# ATmega324PA register map
Vendor: Atmel; File version: 1.0
CPU: other r0p0, little endian, no MPU, no FPU, 4 interrupt priority bits
Registers are 8-bit, read-write, reset 0x0 unless marked. A register's access mark holds for its fields unless they carry their own. Offsets are from the block's base; [hi:lo] are bit positions.

## TC2 — Timer/Counter, 8-bit Async
Base 0x00000037
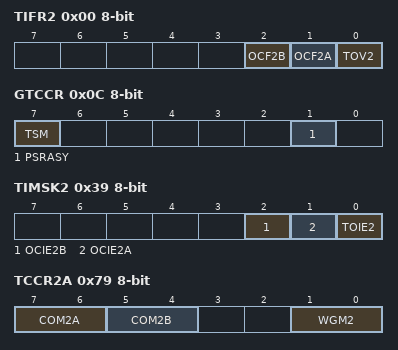
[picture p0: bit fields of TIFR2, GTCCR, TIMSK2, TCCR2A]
0x00 TIFR2 — Timer/Counter Interrupt Flag Register
  [2] OCF2B — Output Compare Flag 2B
  [1] OCF2A — Output Compare Flag 2A
  [0] TOV2 — Timer/Counter2 Overflow Flag
0x0C GTCCR — General Timer Counter Control register
  [7] TSM — Timer/Counter Synchronization Mode
  [1] PSRASY — Prescaler Reset Timer/Counter2
0x39 TIMSK2 — Timer/Counter Interrupt Mask register
  [2] OCIE2B — Timer/Counter2 Output Compare Match B Interrupt Enable
  [1] OCIE2A — Timer/Counter2 Output Compare Match A Interrupt Enable
  [0] TOIE2 — Timer/Counter2 Overflow Interrupt Enable
0x79 TCCR2A — Timer/Counter2 Control Register A
  [7:6] COM2A — Compare Output Mode bits
  [5:4] COM2B — Compare Output Mode bits
  [1:0] WGM2 — Waveform Genration Mode
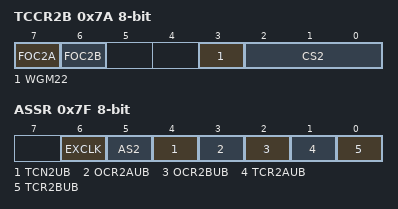
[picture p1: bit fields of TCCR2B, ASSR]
0x7A TCCR2B — Timer/Counter2 Control Register B
  [7] FOC2A — Force Output Compare A
  [6] FOC2B — Force Output Compare B
  [3] WGM22 — Waveform Generation Mode
  [2:0] CS2 — Clock Select bits
    0=No Clock Source (Stopped); 1=Running, No Prescaling; 2=Running, CLK/8; 3=Running, CLK/32; 4=Running, CLK/64; 5=Running, CLK/128; 6=Running, CLK/256; 7=Running, CLK/1024
0x7B TCNT2 — Timer/Counter2
  [7:0] TCNT2 — Timer/Counter2 bits
0x7C OCR2A — Timer/Counter2 Output Compare Register A
  [7:0] OCR2A — Timer/Counter0 Output Compare A bits
0x7D OCR2B — Timer/Counter2 Output Compare Register B
  [7:0] OCR2B — Timer/Counter2 Output Compare B bits
0x7F ASSR — Asynchronous Status Register
  [6] EXCLK — Enable External Clock Input
  [5] AS2 — Asynchronous Timer/Counter2
  [4] TCN2UB — Timer/Counter2 Update Busy
  [3] OCR2AUB — Output Compare Register2 Update Busy
  [2] OCR2BUB — Output Compare Register 2 Update Busy
  [1] TCR2AUB — Timer/Counter Control Register2 Update Busy
  [0] TCR2BUB — Timer/Counter Control Register2 Update Busy

## TWI — Two Wire Serial Interface
Base 0x000000B8
0x00 TWBR — TWI Bit Rate register
  [7:0] TWBR — TWI bit rate bits
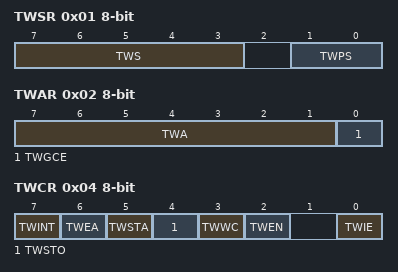
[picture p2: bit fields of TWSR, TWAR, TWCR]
0x01 TWSR — TWI Status Register
  [7:3] TWS — TWI Status
  [1:0] TWPS — TWI Prescaler
    0=1; 1=4; 2=16; 3=64
0x02 TWAR — TWI (Slave) Address register
  [7:1] TWA — TWI (Slave) Address register Bits
  [0] TWGCE — TWI General Call Recognition Enable Bit
0x03 TWDR — TWI Data register
  [7:0] TWD — TWI data bits
0x04 TWCR — TWI Control Register
  [7] TWINT — TWI Interrupt Flag
  [6] TWEA — TWI Enable Acknowledge Bit
  [5] TWSTA — TWI Start Condition Bit
  [4] TWSTO — TWI Stop Condition Bit
  [3] TWWC — TWI Write Collition Flag
  [2] TWEN — TWI Enable Bit
  [0] TWIE — TWI Interrupt Enable
0x05 TWAMR — TWI (Slave) Address Mask Register
  [7:1] TWAM

## USART0 — USART
Base 0x000000C0
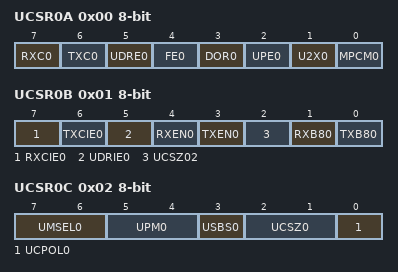
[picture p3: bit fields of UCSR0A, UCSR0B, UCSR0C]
0x00 UCSR0A — USART Control and Status Register A
  [7] RXC0 — USART Receive Complete
  [6] TXC0 — USART Transmitt Complete
  [5] UDRE0 — USART Data Register Empty
  [4] FE0 — Framing Error
  [3] DOR0 — Data overRun
  [2] UPE0 — Parity Error
  [1] U2X0 — Double the USART transmission speed
  [0] MPCM0 — Multi-processor Communication Mode
0x01 UCSR0B — USART Control and Status Register B
  [7] RXCIE0 — RX Complete Interrupt Enable
  [6] TXCIE0 — TX Complete Interrupt Enable
  [5] UDRIE0 — USART Data register Empty Interrupt Enable
  [4] RXEN0 — Receiver Enable
  [3] TXEN0 — Transmitter Enable
  [2] UCSZ02 — Character Size
  [1] RXB80 — Receive Data Bit 8
  [0] TXB80 — Transmit Data Bit 8
0x02 UCSR0C — USART Control and Status Register C
  [7:6] UMSEL0 — USART Mode Select
    0=Asynchronous USART; 1=Synchronous USART; 3=Master SPI
  [5:4] UPM0 — Parity Mode Bits
    0=Disabled; 2=Enabled, Even Parity; 3=Enabled, Odd Parity
  [3] USBS0 — Stop Bit Select
    0=1-bit; 1=2-bit
  [2:1] UCSZ0 — Character Size
  [0] UCPOL0 — Clock Polarity
0x04 UBRR0 16-bit (reset mask 0xFF) — USART Baud Rate Register Bytes
0x06 UDR0 — USART I/O Data Register
  [7:0] UDR0 — USART I/O Data bits

## USART1 — USART
Base 0x000000C8
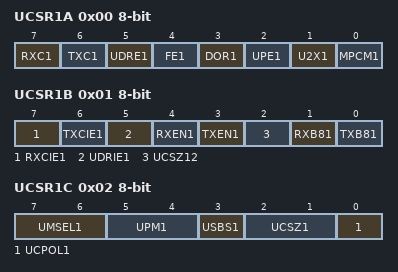
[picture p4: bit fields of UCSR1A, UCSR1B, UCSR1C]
0x00 UCSR1A — USART Control and Status Register A
  [7] RXC1 — USART Receive Complete
  [6] TXC1 — USART Transmitt Complete
  [5] UDRE1 — USART Data Register Empty
  [4] FE1 — Framing Error
  [3] DOR1 — Data overRun
  [2] UPE1 — Parity Error
  [1] U2X1 — Double the USART transmission speed
  [0] MPCM1 — Multi-processor Communication Mode
0x01 UCSR1B — USART Control and Status Register B
  [7] RXCIE1 — RX Complete Interrupt Enable
  [6] TXCIE1 — TX Complete Interrupt Enable
  [5] UDRIE1 — USART Data register Empty Interrupt Enable
  [4] RXEN1 — Receiver Enable
  [3] TXEN1 — Transmitter Enable
  [2] UCSZ12 — Character Size
  [1] RXB81 — Receive Data Bit 8
  [0] TXB81 — Transmit Data Bit 8
0x02 UCSR1C — USART Control and Status Register C
  [7:6] UMSEL1 — USART Mode Select
    0=Asynchronous USART; 1=Synchronous USART; 3=Master SPI
  [5:4] UPM1 — Parity Mode Bits
    0=Disabled; 2=Enabled, Even Parity; 3=Enabled, Odd Parity
  [3] USBS1 — Stop Bit Select
    0=1-bit; 1=2-bit
  [2:1] UCSZ1 — Character Size
  [0] UCPOL1 — Clock Polarity
0x04 UBRR1 16-bit (reset mask 0xFF) — USART Baud Rate Register Bytes
  [11:0] UBRR1 — USART Baud Rate bits
0x06 UDR1 — USART I/O Data Register
  [7:0] UDR1 — USART I/O Data bits

## WDT — Watchdog Timer
Base 0x00000060
0x00 WDTCSR — Watchdog Timer Control Register
  [7] WDIF — Watchdog Timeout Interrupt Flag
  [6] WDIE — Watchdog Timeout Interrupt Enable
  [4] WDCE — Watchdog Change Enable
  [3] WDE — Watch Dog Enable
  [5:0] WDP — Watchdog Timer Prescaler Bits
    0=Oscillator Cycles 2K; 1=Oscillator Cycles 4K; 2=Oscillator Cycles 8K; 3=Oscillator Cycles 16K; 4=Oscillator Cycles 32K; 5=Oscillator Cycles 64K; 6=Oscillator Cycles 128K; 7=Oscillator Cycles 256K
